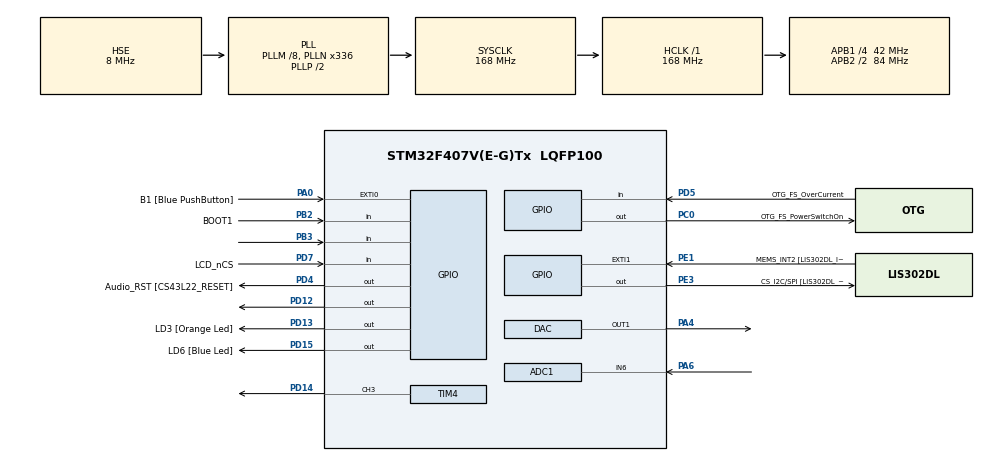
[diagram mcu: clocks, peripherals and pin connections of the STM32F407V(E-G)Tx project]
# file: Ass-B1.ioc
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ADC1.Channel-4\#ChannelRegularConversion=ADC_CHANNEL_6
ADC1.ContinuousConvMode=DISABLE
ADC1.DMAContinuousRequests=ENABLE
ADC1.EOCSelection=ADC_EOC_SEQ_CONV
ADC1.ExternalTrigConv=ADC_EXTERNALTRIGCONV_T8_TRGO
ADC1.InjNumberOfConversion=0
ADC1.NbrOfConversionFlag=1
ADC1.Rank-4\#ChannelRegularConversion=1
ADC1.Resolution=ADC_RESOLUTION_8B
ADC1.SamplingTime-4\#ChannelRegularConversion=ADC_SAMPLETIME_15CYCLES
ADC1.ScanConvMode=DISABLE
ADC1.master=1
DAC.DAC_Trigger=DAC_TRIGGER_T2_TRGO
Dma.ADC1.2.Direction=DMA_PERIPH_TO_MEMORY
Dma.ADC1.2.FIFOMode=DMA_FIFOMODE_DISABLE
Dma.ADC1.2.Instance=DMA2_Stream0
Dma.ADC1.2.MemDataAlignment=DMA_MDATAALIGN_HALFWORD
Dma.ADC1.2.MemInc=DMA_MINC_ENABLE
Dma.ADC1.2.Mode=DMA_CIRCULAR
Dma.ADC1.2.PeriphDataAlignment=DMA_PDATAALIGN_HALFWORD
Dma.ADC1.2.PeriphInc=DMA_PINC_DISABLE
Dma.ADC1.2.Priority=DMA_PRIORITY_LOW
Dma.DAC1.1.Direction=DMA_MEMORY_TO_PERIPH
Dma.DAC1.1.FIFOMode=DMA_FIFOMODE_DISABLE
Dma.DAC1.1.Instance=DMA1_Stream5
Dma.DAC1.1.MemDataAlignment=DMA_MDATAALIGN_WORD
Dma.DAC1.1.MemInc=DMA_MINC_ENABLE
Dma.DAC1.1.Mode=DMA_CIRCULAR
Dma.DAC1.1.PeriphDataAlignment=DMA_PDATAALIGN_WORD
Dma.DAC1.1.PeriphInc=DMA_PINC_DISABLE
Dma.DAC1.1.Priority=DMA_PRIORITY_LOW
Dma.Request0=TIM4_CH3
Dma.Request1=DAC1
Dma.Request2=ADC1
Dma.TIM4_CH3.0.Direction=DMA_MEMORY_TO_PERIPH
Dma.TIM4_CH3.0.FIFOMode=DMA_FIFOMODE_DISABLE
Dma.TIM4_CH3.0.Instance=DMA1_Stream7
Dma.TIM4_CH3.0.MemDataAlignment=DMA_MDATAALIGN_HALFWORD
Dma.TIM4_CH3.0.MemInc=DMA_MINC_ENABLE
Dma.TIM4_CH3.0.Mode=DMA_CIRCULAR
Dma.TIM4_CH3.0.PeriphDataAlignment=DMA_PDATAALIGN_HALFWORD
Dma.TIM4_CH3.0.PeriphInc=DMA_PINC_DISABLE
Dma.TIM4_CH3.0.Priority=DMA_PRIORITY_LOW
Mcu.Family=STM32F4
Mcu.Name=STM32F407V(E-G)Tx
Mcu.Package=LQFP100
NVIC.EXTI0_IRQn=true\:0\:0\:false\:false\:true\:true\:true\:true
NVIC.PriorityGroup=NVIC_PRIORITYGROUP_0
NVIC.TIM3_IRQn=true\:0\:0\:false\:false\:true\:true\:true\:true
PA0-WKUP.GPIO_Label=B1 [Blue PushButton]
PA0-WKUP.Signal=GPXTI0
PA10.GPIO_Label=OTG_FS_ID
PA10.GPIO_Mode=GPIO_MODE_AF_PP
PA10.GPIO_PuPd=GPIO_NOPULL
PA10.GPIO_Speed=GPIO_SPEED_FREQ_LOW
PA10.Signal=USB_OTG_FS_ID
PA11.GPIO_Label=OTG_FS_DM
PA11.GPIO_Mode=GPIO_MODE_AF_PP
PA11.GPIO_PuPd=GPIO_NOPULL
PA11.GPIO_Speed=GPIO_SPEED_FREQ_LOW
PA11.Signal=USB_OTG_FS_DM
PA12.GPIO_Label=OTG_FS_DP
PA12.GPIO_Mode=GPIO_MODE_AF_PP
PA12.GPIO_PuPd=GPIO_NOPULL
PA12.GPIO_Speed=GPIO_SPEED_FREQ_LOW
PA12.Signal=USB_OTG_FS_DP
PA13.GPIO_Label=SWDIO
PA13.Mode=Serial_Wire
PA13.Signal=SYS_JTMS-SWDIO
PA14.GPIO_Label=SWCLK
PA14.Mode=Serial_Wire
PA14.Signal=SYS_JTCK-SWCLK
PA4.Signal=COMP_DAC1_group
PA6.Signal=ADCx_IN6
PA7.GPIO_Label=SPI1_MOSI [LIS302DL_SDA/SDI/SDO]
PA7.GPIO_Mode=GPIO_MODE_AF_PP
PA7.GPIO_PuPd=GPIO_NOPULL
PA7.GPIO_Speed=GPIO_SPEED_FREQ_LOW
PA7.Signal=SPI1_MOSI
PA9.GPIO_Label=VBUS_FS
PA9.GPIO_Mode=GPIO_MODE_INPUT
PA9.GPIO_PuPd=GPIO_NOPULL
PA9.Signal=USB_OTG_FS_VBUS
PB10.GPIO_Label=CLK_IN [MP45DT02_CLK]
PB10.GPIO_Mode=GPIO_MODE_AF_PP
PB10.GPIO_PuPd=GPIO_NOPULL
PB10.GPIO_Speed=GPIO_SPEED_FREQ_LOW
PB10.Signal=I2S2_CK
PB2.GPIO_Label=BOOT1
PB2.GPIO_Mode=GPIO_MODE_INPUT
PB2.GPIO_PuPd=GPIO_NOPULL
PB2.Signal=GPIO_Input
PB3.Signal=GPIO_Input
PB6.GPIO_Label=Audio_SCL [CS43L22_SCL]
PB6.GPIO_Mode=GPIO_MODE_AF_OD
PB6.GPIO_Pu=GPIO_PULLUP
PB6.GPIO_PuPd=GPIO_NOPULL
PB6.GPIO_Speed=GPIO_SPEED_FREQ_LOW
PB6.Signal=I2C1_SCL
PB9.GPIO_Label=Audio_SDA [CS43L22_SDA]
PB9.GPIO_Mode=GPIO_MODE_AF_OD
PB9.GPIO_Pu=GPIO_PULLUP
PB9.GPIO_PuPd=GPIO_NOPULL
PB9.GPIO_Speed=GPIO_SPEED_FREQ_LOW
PB9.Signal=I2C1_SDA
PC0.GPIO_Label=OTG_FS_PowerSwitchOn
PC0.GPIO_PuPd=GPIO_NOPULL
PC0.GPIO_Speed=GPIO_SPEED_FREQ_LOW
PC0.PinState=GPIO_PIN_SET
PC0.Signal=GPIO_Output
PC10.GPIO_Label=I2S3_SCK [CS43L22_SCLK]
PC10.GPIO_Mode=GPIO_MODE_AF_PP
PC10.GPIO_PuPd=GPIO_NOPULL
PC10.GPIO_Speed=GPIO_SPEED_FREQ_LOW
PC10.Signal=I2S3_CK
PC12.GPIO_Label=I2S3_SD [CS43L22_SDIN]
PC12.GPIO_Mode=GPIO_MODE_AF_PP
PC12.GPIO_PuPd=GPIO_NOPULL
PC12.GPIO_Speed=GPIO_SPEED_FREQ_LOW
PC12.Signal=I2S3_SD
PC14-OSC32_IN.GPIO_Label=PC14-OSC32_IN
PC14-OSC32_IN.Mode=LSE-External-Oscillator
PC14-OSC32_IN.Signal=RCC_OSC32_IN
PC15-OSC32_OUT.GPIO_Label=PC15-OSC32_OUT
PC15-OSC32_OUT.Mode=LSE-External-Oscillator
PC15-OSC32_OUT.Signal=RCC_OSC32_OUT
PC3.GPIO_Label=PDM_OUT [MP45DT02_DOUT]
PC3.GPIO_Mode=GPIO_MODE_AF_PP
PC3.GPIO_PuPd=GPIO_NOPULL
PC3.GPIO_Speed=GPIO_SPEED_FREQ_LOW
PC3.Signal=I2S2_SD
PC7.GPIO_Label=I2S3_MCK [CS43L22_MCLK]
PC7.GPIO_Mode=GPIO_MODE_AF_PP
PC7.GPIO_PuPd=GPIO_NOPULL
PC7.GPIO_Speed=GPIO_SPEED_FREQ_LOW
PC7.Signal=I2S3_MCK
PD12.Signal=GPIO_Output
PD13.GPIO_Label=LD3 [Orange Led]
PD13.GPIO_PuPd=GPIO_NOPULL
PD13.GPIO_Speed=GPIO_SPEED_FREQ_LOW
PD13.Signal=GPIO_Output
PD14.Signal=S_TIM4_CH3
PD15.GPIO_Label=LD6 [Blue Led]
PD15.GPIO_PuPd=GPIO_NOPULL
PD15.GPIO_Speed=GPIO_SPEED_FREQ_LOW
PD15.Signal=GPIO_Output
PD4.GPIO_Label=Audio_RST [CS43L22_RESET]
PD4.GPIO_PuPd=GPIO_NOPULL
PD4.GPIO_Speed=GPIO_SPEED_FREQ_LOW
PD4.Signal=GPIO_Output
PD5.GPIO_Label=OTG_FS_OverCurrent
PD5.GPIO_Mode=GPIO_MODE_INPUT
PD5.GPIO_PuPd=GPIO_NOPULL
PD5.Signal=GPIO_Input
PD7.GPIO_Label=LCD_nCS
PD7.GPIO_PuPd=GPIO_PULLUP
PD7.Signal=GPIO_Input
PE1.GPIO_Label=MEMS_INT2 [LIS302DL_INT2]
PE1.GPIO_ModeDefaultEXTI=GPIO_MODE_EVT_RISING
PE1.GPIO_PuPd=GPIO_NOPULL
PE1.Signal=GPXTI1
PE3.GPIO_Label=CS_I2C/SPI [LIS302DL_CS_I2C/SPI]
PE3.GPIO_PuPd=GPIO_NOPULL
PE3.GPIO_Speed=GPIO_SPEED_FREQ_LOW
PE3.Signal=GPIO_Output
PH0-OSC_IN.GPIO_Label=PH0-OSC_IN
PH0-OSC_IN.Mode=HSE-External-Oscillator
PH0-OSC_IN.Signal=RCC_OSC_IN
PH1-OSC_OUT.GPIO_Label=PH1-OSC_OUT
PH1-OSC_OUT.Mode=HSE-External-Oscillator
PH1-OSC_OUT.Signal=RCC_OSC_OUT
ProjectManager.HeapSize=0x200
ProjectManager.StackSize=0x400
ProjectManager.TargetToolchain=STM32CubeIDE
RCC.48MHZClocksFreq_Value=48000000
RCC.AHBFreq_Value=168000000
RCC.APB1CLKDivider=RCC_HCLK_DIV4
RCC.APB1Freq_Value=42000000
RCC.APB1TimFreq_Value=84000000
RCC.APB2CLKDivider=RCC_HCLK_DIV2
RCC.APB2Freq_Value=84000000
RCC.APB2TimFreq_Value=168000000
RCC.CortexFreq_Value=168000000
RCC.HCLKFreq_Value=168000000
RCC.HSE_VALUE=8000000
RCC.HSI_VALUE=16000000
RCC.PLLM=8
RCC.PLLN=336
RCC.PLLQ=7
RCC.PLLSourceVirtual=RCC_PLLSOURCE_HSE
RCC.SYSCLKFreq_VALUE=168000000
RCC.SYSCLKSource=RCC_SYSCLKSOURCE_PLLCLK
RCC.VCOOutputFreq_Value=336000000
SH.ADCx_IN6.0=ADC1_IN6,IN6
SH.COMP_DAC1_group.0=DAC_OUT1,DAC_OUT1
SH.S_TIM4_CH3.0=TIM4_CH3,PWM Generation3 CH3
TIM2.Period=999
TIM2.Prescaler=89
TIM2.TIM_MasterOutputTrigger=TIM_TRGO_UPDATE
TIM3.Period=59999
TIM3.Prescaler=13
TIM4.Channel-PWM\ Generation3\ CH3=TIM_CHANNEL_3
TIM4.Period=1999
TIM4.Prescaler=209
TIM8.Period=999
TIM8.Prescaler=99
TIM8.RepetitionCounter=0
TIM8.TIM_MasterOutputTrigger=TIM_TRGO_UPDATE
TIM8.TIM_MasterSlaveMode=TIM_MASTERSLAVEMODE_DISABLE
VP_TIM2_VS_ClockSourceINT.Mode=Internal
VP_TIM3_VS_ClockSourceINT.Mode=Internal
VP_TIM4_VS_ClockSourceINT.Mode=Internal
VP_TIM8_VS_ClockSourceINT.Mode=Internal
board=STM32F407G-DISC1

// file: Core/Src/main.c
/* USER CODE BEGIN Header */
/**
  ******************************************************************************
  * @file           : main.c
  * @brief          : Main program body
  ******************************************************************************
  * @attention
  *
  * Copyright (c) 2023 STMicroelectronics.
  * All rights reserved.
  *
  * This software is licensed under terms that can be found in the LICENSE file
  * in the root directory of this software component.
  * If no LICENSE file comes with this software, it is provided AS-IS.
  *
  ******************************************************************************
  */
/* USER CODE END Header */
#include "main.h"

/* USER CODE BEGIN Includes */
#include <stdio.h>
void Ass_1B_main(void);
/* USER CODE END Includes */

ADC_HandleTypeDef hadc1;
DMA_HandleTypeDef hdma_adc1;

DAC_HandleTypeDef hdac;
DMA_HandleTypeDef hdma_dac1;

TIM_HandleTypeDef htim2;
TIM_HandleTypeDef htim3;
TIM_HandleTypeDef htim4;
TIM_HandleTypeDef htim8;
DMA_HandleTypeDef hdma_tim4_ch3;

void SystemClock_Config(void);
static void MX_GPIO_Init(void);
static void MX_DMA_Init(void);
static void MX_TIM3_Init(void);
static void MX_TIM4_Init(void);
static void MX_DAC_Init(void);
static void MX_TIM2_Init(void);
static void MX_ADC1_Init(void);
static void MX_TIM8_Init(void);

/* USER CODE BEGIN 0 */
extern void initialise_monitor_handles(void);
/* USER CODE END 0 */

int main(void)
{
  /* USER CODE BEGIN 1 */
initialise_monitor_handles();
  /* USER CODE END 1 */

  /* MCU Configuration--------------------------------------------------------*/

  /* Reset of all peripherals, Initializes the Flash interface and the Systick. */
  HAL_Init();

  /* Configure the system clock */
  SystemClock_Config();

  /* Initialize all configured peripherals */
  MX_GPIO_Init();
  MX_DMA_Init();
  MX_TIM3_Init();
  MX_TIM4_Init();
  MX_DAC_Init();
  MX_TIM2_Init();
  MX_ADC1_Init();
  MX_TIM8_Init();
  /* USER CODE BEGIN 2 */
  Ass_1B_main();
  /* USER CODE END 2 */

  /* Infinite loop */
  while (1)
  {

  }
}

void SystemClock_Config(void)
{
  RCC_OscInitTypeDef RCC_OscInitStruct = {0};
  RCC_ClkInitTypeDef RCC_ClkInitStruct = {0};

  /** Configure the main internal regulator output voltage
  */
  __HAL_RCC_PWR_CLK_ENABLE();
  __HAL_PWR_VOLTAGESCALING_CONFIG(PWR_REGULATOR_VOLTAGE_SCALE1);

  /** Initializes the RCC Oscillators according to the specified parameters
  * in the RCC_OscInitTypeDef structure.
  */
  RCC_OscInitStruct.OscillatorType = RCC_OSCILLATORTYPE_HSE;
  RCC_OscInitStruct.HSEState = RCC_HSE_ON;
  RCC_OscInitStruct.PLL.PLLState = RCC_PLL_ON;
  RCC_OscInitStruct.PLL.PLLSource = RCC_PLLSOURCE_HSE;
  RCC_OscInitStruct.PLL.PLLM = 8;
  RCC_OscInitStruct.PLL.PLLN = 336;
  RCC_OscInitStruct.PLL.PLLP = RCC_PLLP_DIV2;
  RCC_OscInitStruct.PLL.PLLQ = 7;
  if (HAL_RCC_OscConfig(&RCC_OscInitStruct) != HAL_OK)
  {
    Error_Handler();
  }

  /** Initializes the CPU, AHB and APB buses clocks
  */
  RCC_ClkInitStruct.ClockType = RCC_CLOCKTYPE_HCLK|RCC_CLOCKTYPE_SYSCLK
                              |RCC_CLOCKTYPE_PCLK1|RCC_CLOCKTYPE_PCLK2;
  RCC_ClkInitStruct.SYSCLKSource = RCC_SYSCLKSOURCE_PLLCLK;
  RCC_ClkInitStruct.AHBCLKDivider = RCC_SYSCLK_DIV1;
  RCC_ClkInitStruct.APB1CLKDivider = RCC_HCLK_DIV4;
  RCC_ClkInitStruct.APB2CLKDivider = RCC_HCLK_DIV2;

  if (HAL_RCC_ClockConfig(&RCC_ClkInitStruct, FLASH_LATENCY_5) != HAL_OK)
  {
    Error_Handler();
  }
}

static void MX_ADC1_Init(void)
{

  ADC_ChannelConfTypeDef sConfig = {0};

  /** Configure the global features of the ADC (Clock, Resolution, Data Alignment and number of conversion)
  */
  hadc1.Instance = ADC1;
  hadc1.Init.ClockPrescaler = ADC_CLOCK_SYNC_PCLK_DIV4;
  hadc1.Init.Resolution = ADC_RESOLUTION_8B;
  hadc1.Init.ScanConvMode = DISABLE;
  hadc1.Init.ContinuousConvMode = DISABLE;
  hadc1.Init.DiscontinuousConvMode = DISABLE;
  hadc1.Init.ExternalTrigConvEdge = ADC_EXTERNALTRIGCONVEDGE_RISING;
  hadc1.Init.ExternalTrigConv = ADC_EXTERNALTRIGCONV_T8_TRGO;
  hadc1.Init.DataAlign = ADC_DATAALIGN_RIGHT;
  hadc1.Init.NbrOfConversion = 1;
  hadc1.Init.DMAContinuousRequests = ENABLE;
  hadc1.Init.EOCSelection = ADC_EOC_SEQ_CONV;
  if (HAL_ADC_Init(&hadc1) != HAL_OK)
  {
    Error_Handler();
  }

  /** Configure for the selected ADC regular channel its corresponding rank in the sequencer and its sample time.
  */
  sConfig.Channel = ADC_CHANNEL_6;
  sConfig.Rank = 1;
  sConfig.SamplingTime = ADC_SAMPLETIME_15CYCLES;
  if (HAL_ADC_ConfigChannel(&hadc1, &sConfig) != HAL_OK)
  {
    Error_Handler();
  }

}

static void MX_DAC_Init(void)
{

  DAC_ChannelConfTypeDef sConfig = {0};

  /** DAC Initialization
  */
  hdac.Instance = DAC;
  if (HAL_DAC_Init(&hdac) != HAL_OK)
  {
    Error_Handler();
  }

  /** DAC channel OUT1 config
  */
  sConfig.DAC_Trigger = DAC_TRIGGER_T2_TRGO;
  sConfig.DAC_OutputBuffer = DAC_OUTPUTBUFFER_ENABLE;
  if (HAL_DAC_ConfigChannel(&hdac, &sConfig, DAC_CHANNEL_1) != HAL_OK)
  {
    Error_Handler();
  }

}

static void MX_TIM2_Init(void)
{

  TIM_ClockConfigTypeDef sClockSourceConfig = {0};
  TIM_MasterConfigTypeDef sMasterConfig = {0};

  htim2.Instance = TIM2;
  htim2.Init.Prescaler = 89;
  htim2.Init.CounterMode = TIM_COUNTERMODE_UP;
  htim2.Init.Period = 999;
  htim2.Init.ClockDivision = TIM_CLOCKDIVISION_DIV1;
  htim2.Init.AutoReloadPreload = TIM_AUTORELOAD_PRELOAD_DISABLE;
  if (HAL_TIM_Base_Init(&htim2) != HAL_OK)
  {
    Error_Handler();
  }
  sClockSourceConfig.ClockSource = TIM_CLOCKSOURCE_INTERNAL;
  if (HAL_TIM_ConfigClockSource(&htim2, &sClockSourceConfig) != HAL_OK)
  {
    Error_Handler();
  }
  sMasterConfig.MasterOutputTrigger = TIM_TRGO_UPDATE;
  sMasterConfig.MasterSlaveMode = TIM_MASTERSLAVEMODE_DISABLE;
  if (HAL_TIMEx_MasterConfigSynchronization(&htim2, &sMasterConfig) != HAL_OK)
  {
    Error_Handler();
  }

}

static void MX_TIM3_Init(void)
{

  TIM_ClockConfigTypeDef sClockSourceConfig = {0};
  TIM_MasterConfigTypeDef sMasterConfig = {0};

  htim3.Instance = TIM3;
  htim3.Init.Prescaler = 13;
  htim3.Init.CounterMode = TIM_COUNTERMODE_UP;
  htim3.Init.Period = 59999;
  htim3.Init.ClockDivision = TIM_CLOCKDIVISION_DIV1;
  htim3.Init.AutoReloadPreload = TIM_AUTORELOAD_PRELOAD_DISABLE;
  if (HAL_TIM_Base_Init(&htim3) != HAL_OK)
  {
    Error_Handler();
  }
  sClockSourceConfig.ClockSource = TIM_CLOCKSOURCE_INTERNAL;
  if (HAL_TIM_ConfigClockSource(&htim3, &sClockSourceConfig) != HAL_OK)
  {
    Error_Handler();
  }
  sMasterConfig.MasterOutputTrigger = TIM_TRGO_RESET;
  sMasterConfig.MasterSlaveMode = TIM_MASTERSLAVEMODE_DISABLE;
  if (HAL_TIMEx_MasterConfigSynchronization(&htim3, &sMasterConfig) != HAL_OK)
  {
    Error_Handler();
  }

}

static void MX_TIM4_Init(void)
{

  TIM_ClockConfigTypeDef sClockSourceConfig = {0};
  TIM_MasterConfigTypeDef sMasterConfig = {0};
  TIM_OC_InitTypeDef sConfigOC = {0};

  htim4.Instance = TIM4;
  htim4.Init.Prescaler = 209;
  htim4.Init.CounterMode = TIM_COUNTERMODE_UP;
  htim4.Init.Period = 1999;
  htim4.Init.ClockDivision = TIM_CLOCKDIVISION_DIV1;
  htim4.Init.AutoReloadPreload = TIM_AUTORELOAD_PRELOAD_DISABLE;
  if (HAL_TIM_Base_Init(&htim4) != HAL_OK)
  {
    Error_Handler();
  }
  sClockSourceConfig.ClockSource = TIM_CLOCKSOURCE_INTERNAL;
  if (HAL_TIM_ConfigClockSource(&htim4, &sClockSourceConfig) != HAL_OK)
  {
    Error_Handler();
  }
  if (HAL_TIM_PWM_Init(&htim4) != HAL_OK)
  {
    Error_Handler();
  }
  sMasterConfig.MasterOutputTrigger = TIM_TRGO_RESET;
  sMasterConfig.MasterSlaveMode = TIM_MASTERSLAVEMODE_DISABLE;
  if (HAL_TIMEx_MasterConfigSynchronization(&htim4, &sMasterConfig) != HAL_OK)
  {
    Error_Handler();
  }
  sConfigOC.OCMode = TIM_OCMODE_PWM1;
  sConfigOC.Pulse = 0;
  sConfigOC.OCPolarity = TIM_OCPOLARITY_HIGH;
  sConfigOC.OCFastMode = TIM_OCFAST_DISABLE;
  if (HAL_TIM_PWM_ConfigChannel(&htim4, &sConfigOC, TIM_CHANNEL_3) != HAL_OK)
  {
    Error_Handler();
  }
  HAL_TIM_MspPostInit(&htim4);

}

static void MX_TIM8_Init(void)
{

  TIM_ClockConfigTypeDef sClockSourceConfig = {0};
  TIM_MasterConfigTypeDef sMasterConfig = {0};

  htim8.Instance = TIM8;
  htim8.Init.Prescaler = 99;
  htim8.Init.CounterMode = TIM_COUNTERMODE_UP;
  htim8.Init.Period = 999;
  htim8.Init.ClockDivision = TIM_CLOCKDIVISION_DIV1;
  htim8.Init.RepetitionCounter = 0;
  htim8.Init.AutoReloadPreload = TIM_AUTORELOAD_PRELOAD_DISABLE;
  if (HAL_TIM_Base_Init(&htim8) != HAL_OK)
  {
    Error_Handler();
  }
  sClockSourceConfig.ClockSource = TIM_CLOCKSOURCE_INTERNAL;
  if (HAL_TIM_ConfigClockSource(&htim8, &sClockSourceConfig) != HAL_OK)
  {
    Error_Handler();
  }
  sMasterConfig.MasterOutputTrigger = TIM_TRGO_UPDATE;
  sMasterConfig.MasterSlaveMode = TIM_MASTERSLAVEMODE_DISABLE;
  if (HAL_TIMEx_MasterConfigSynchronization(&htim8, &sMasterConfig) != HAL_OK)
  {
    Error_Handler();
  }

}

static void MX_DMA_Init(void)
{

  /* DMA controller clock enable */
  __HAL_RCC_DMA1_CLK_ENABLE();
  __HAL_RCC_DMA2_CLK_ENABLE();

}

static void MX_GPIO_Init(void)
{
  GPIO_InitTypeDef GPIO_InitStruct = {0};

  /* GPIO Ports Clock Enable */
  __HAL_RCC_GPIOE_CLK_ENABLE();
  __HAL_RCC_GPIOC_CLK_ENABLE();
  __HAL_RCC_GPIOH_CLK_ENABLE();
  __HAL_RCC_GPIOA_CLK_ENABLE();
  __HAL_RCC_GPIOB_CLK_ENABLE();
  __HAL_RCC_GPIOD_CLK_ENABLE();

  /*Configure GPIO pin Output Level */
  HAL_GPIO_WritePin(CS_I2C_SPI_GPIO_Port, CS_I2C_SPI_Pin, GPIO_PIN_RESET);

  /*Configure GPIO pin Output Level */
  HAL_GPIO_WritePin(OTG_FS_PowerSwitchOn_GPIO_Port, OTG_FS_PowerSwitchOn_Pin, GPIO_PIN_SET);

  /*Configure GPIO pin Output Level */
  HAL_GPIO_WritePin(GPIOD, GPIO_PIN_12|LD3_Pin|LD6_Pin|Audio_RST_Pin, GPIO_PIN_RESET);

  /*Configure GPIO pin : CS_I2C_SPI_Pin */
  GPIO_InitStruct.Pin = CS_I2C_SPI_Pin;
  GPIO_InitStruct.Mode = GPIO_MODE_OUTPUT_PP;
  GPIO_InitStruct.Pull = GPIO_NOPULL;
  GPIO_InitStruct.Speed = GPIO_SPEED_FREQ_LOW;
  HAL_GPIO_Init(CS_I2C_SPI_GPIO_Port, &GPIO_InitStruct);

  /*Configure GPIO pin : OTG_FS_PowerSwitchOn_Pin */
  GPIO_InitStruct.Pin = OTG_FS_PowerSwitchOn_Pin;
  GPIO_InitStruct.Mode = GPIO_MODE_OUTPUT_PP;
  GPIO_InitStruct.Pull = GPIO_NOPULL;
  GPIO_InitStruct.Speed = GPIO_SPEED_FREQ_LOW;
  HAL_GPIO_Init(OTG_FS_PowerSwitchOn_GPIO_Port, &GPIO_InitStruct);

  /*Configure GPIO pin : PDM_OUT_Pin */
  GPIO_InitStruct.Pin = PDM_OUT_Pin;
  GPIO_InitStruct.Mode = GPIO_MODE_AF_PP;
  GPIO_InitStruct.Pull = GPIO_NOPULL;
  GPIO_InitStruct.Speed = GPIO_SPEED_FREQ_LOW;
  GPIO_InitStruct.Alternate = GPIO_AF5_SPI2;
  HAL_GPIO_Init(PDM_OUT_GPIO_Port, &GPIO_InitStruct);

  /*Configure GPIO pin : B1_Pin */
  GPIO_InitStruct.Pin = B1_Pin;
  GPIO_InitStruct.Mode = GPIO_MODE_IT_RISING;
  GPIO_InitStruct.Pull = GPIO_NOPULL;
  HAL_GPIO_Init(B1_GPIO_Port, &GPIO_InitStruct);

  /*Configure GPIO pin : SPI1_MOSI_Pin */
  GPIO_InitStruct.Pin = SPI1_MOSI_Pin;
  GPIO_InitStruct.Mode = GPIO_MODE_AF_PP;
  GPIO_InitStruct.Pull = GPIO_NOPULL;
  GPIO_InitStruct.Speed = GPIO_SPEED_FREQ_LOW;
  GPIO_InitStruct.Alternate = GPIO_AF5_SPI1;
  HAL_GPIO_Init(SPI1_MOSI_GPIO_Port, &GPIO_InitStruct);

  /*Configure GPIO pins : BOOT1_Pin PB3 */
  GPIO_InitStruct.Pin = BOOT1_Pin|GPIO_PIN_3;
  GPIO_InitStruct.Mode = GPIO_MODE_INPUT;
  GPIO_InitStruct.Pull = GPIO_NOPULL;
  HAL_GPIO_Init(GPIOB, &GPIO_InitStruct);

  /*Configure GPIO pin : CLK_IN_Pin */
  GPIO_InitStruct.Pin = CLK_IN_Pin;
  GPIO_InitStruct.Mode = GPIO_MODE_AF_PP;
  GPIO_InitStruct.Pull = GPIO_NOPULL;
  GPIO_InitStruct.Speed = GPIO_SPEED_FREQ_LOW;
  GPIO_InitStruct.Alternate = GPIO_AF5_SPI2;
  HAL_GPIO_Init(CLK_IN_GPIO_Port, &GPIO_InitStruct);

  /*Configure GPIO pins : PD12 LD3_Pin LD6_Pin Audio_RST_Pin */
  GPIO_InitStruct.Pin = GPIO_PIN_12|LD3_Pin|LD6_Pin|Audio_RST_Pin;
  GPIO_InitStruct.Mode = GPIO_MODE_OUTPUT_PP;
  GPIO_InitStruct.Pull = GPIO_NOPULL;
  GPIO_InitStruct.Speed = GPIO_SPEED_FREQ_LOW;
  HAL_GPIO_Init(GPIOD, &GPIO_InitStruct);

  /*Configure GPIO pins : I2S3_MCK_Pin I2S3_SCK_Pin I2S3_SD_Pin */
  GPIO_InitStruct.Pin = I2S3_MCK_Pin|I2S3_SCK_Pin|I2S3_SD_Pin;
  GPIO_InitStruct.Mode = GPIO_MODE_AF_PP;
  GPIO_InitStruct.Pull = GPIO_NOPULL;
  GPIO_InitStruct.Speed = GPIO_SPEED_FREQ_LOW;
  GPIO_InitStruct.Alternate = GPIO_AF6_SPI3;
  HAL_GPIO_Init(GPIOC, &GPIO_InitStruct);

  /*Configure GPIO pin : VBUS_FS_Pin */
  GPIO_InitStruct.Pin = VBUS_FS_Pin;
  GPIO_InitStruct.Mode = GPIO_MODE_INPUT;
  GPIO_InitStruct.Pull = GPIO_NOPULL;
  HAL_GPIO_Init(VBUS_FS_GPIO_Port, &GPIO_InitStruct);

  /*Configure GPIO pins : OTG_FS_ID_Pin OTG_FS_DM_Pin OTG_FS_DP_Pin */
  GPIO_InitStruct.Pin = OTG_FS_ID_Pin|OTG_FS_DM_Pin|OTG_FS_DP_Pin;
  GPIO_InitStruct.Mode = GPIO_MODE_AF_PP;
  GPIO_InitStruct.Pull = GPIO_NOPULL;
  GPIO_InitStruct.Speed = GPIO_SPEED_FREQ_LOW;
  GPIO_InitStruct.Alternate = GPIO_AF10_OTG_FS;
  HAL_GPIO_Init(GPIOA, &GPIO_InitStruct);

  /*Configure GPIO pin : OTG_FS_OverCurrent_Pin */
  GPIO_InitStruct.Pin = OTG_FS_OverCurrent_Pin;
  GPIO_InitStruct.Mode = GPIO_MODE_INPUT;
  GPIO_InitStruct.Pull = GPIO_NOPULL;
  HAL_GPIO_Init(OTG_FS_OverCurrent_GPIO_Port, &GPIO_InitStruct);

  /*Configure GPIO pin : LCD_nCS_Pin */
  GPIO_InitStruct.Pin = LCD_nCS_Pin;
  GPIO_InitStruct.Mode = GPIO_MODE_INPUT;
  GPIO_InitStruct.Pull = GPIO_PULLUP;
  HAL_GPIO_Init(LCD_nCS_GPIO_Port, &GPIO_InitStruct);

  /*Configure GPIO pins : Audio_SCL_Pin Audio_SDA_Pin */
  GPIO_InitStruct.Pin = Audio_SCL_Pin|Audio_SDA_Pin;
  GPIO_InitStruct.Mode = GPIO_MODE_AF_OD;
  GPIO_InitStruct.Pull = GPIO_PULLUP;
  GPIO_InitStruct.Speed = GPIO_SPEED_FREQ_LOW;
  GPIO_InitStruct.Alternate = GPIO_AF4_I2C1;
  HAL_GPIO_Init(GPIOB, &GPIO_InitStruct);

  /*Configure GPIO pin : MEMS_INT2_Pin */
  GPIO_InitStruct.Pin = MEMS_INT2_Pin;
  GPIO_InitStruct.Mode = GPIO_MODE_EVT_RISING;
  GPIO_InitStruct.Pull = GPIO_NOPULL;
  HAL_GPIO_Init(MEMS_INT2_GPIO_Port, &GPIO_InitStruct);

  /* EXTI interrupt init*/
  HAL_NVIC_SetPriority(EXTI0_IRQn, 0, 0);
  HAL_NVIC_EnableIRQ(EXTI0_IRQn);

}

void Error_Handler(void)
{
  __disable_irq();
  while (1)
  {
  }
}
